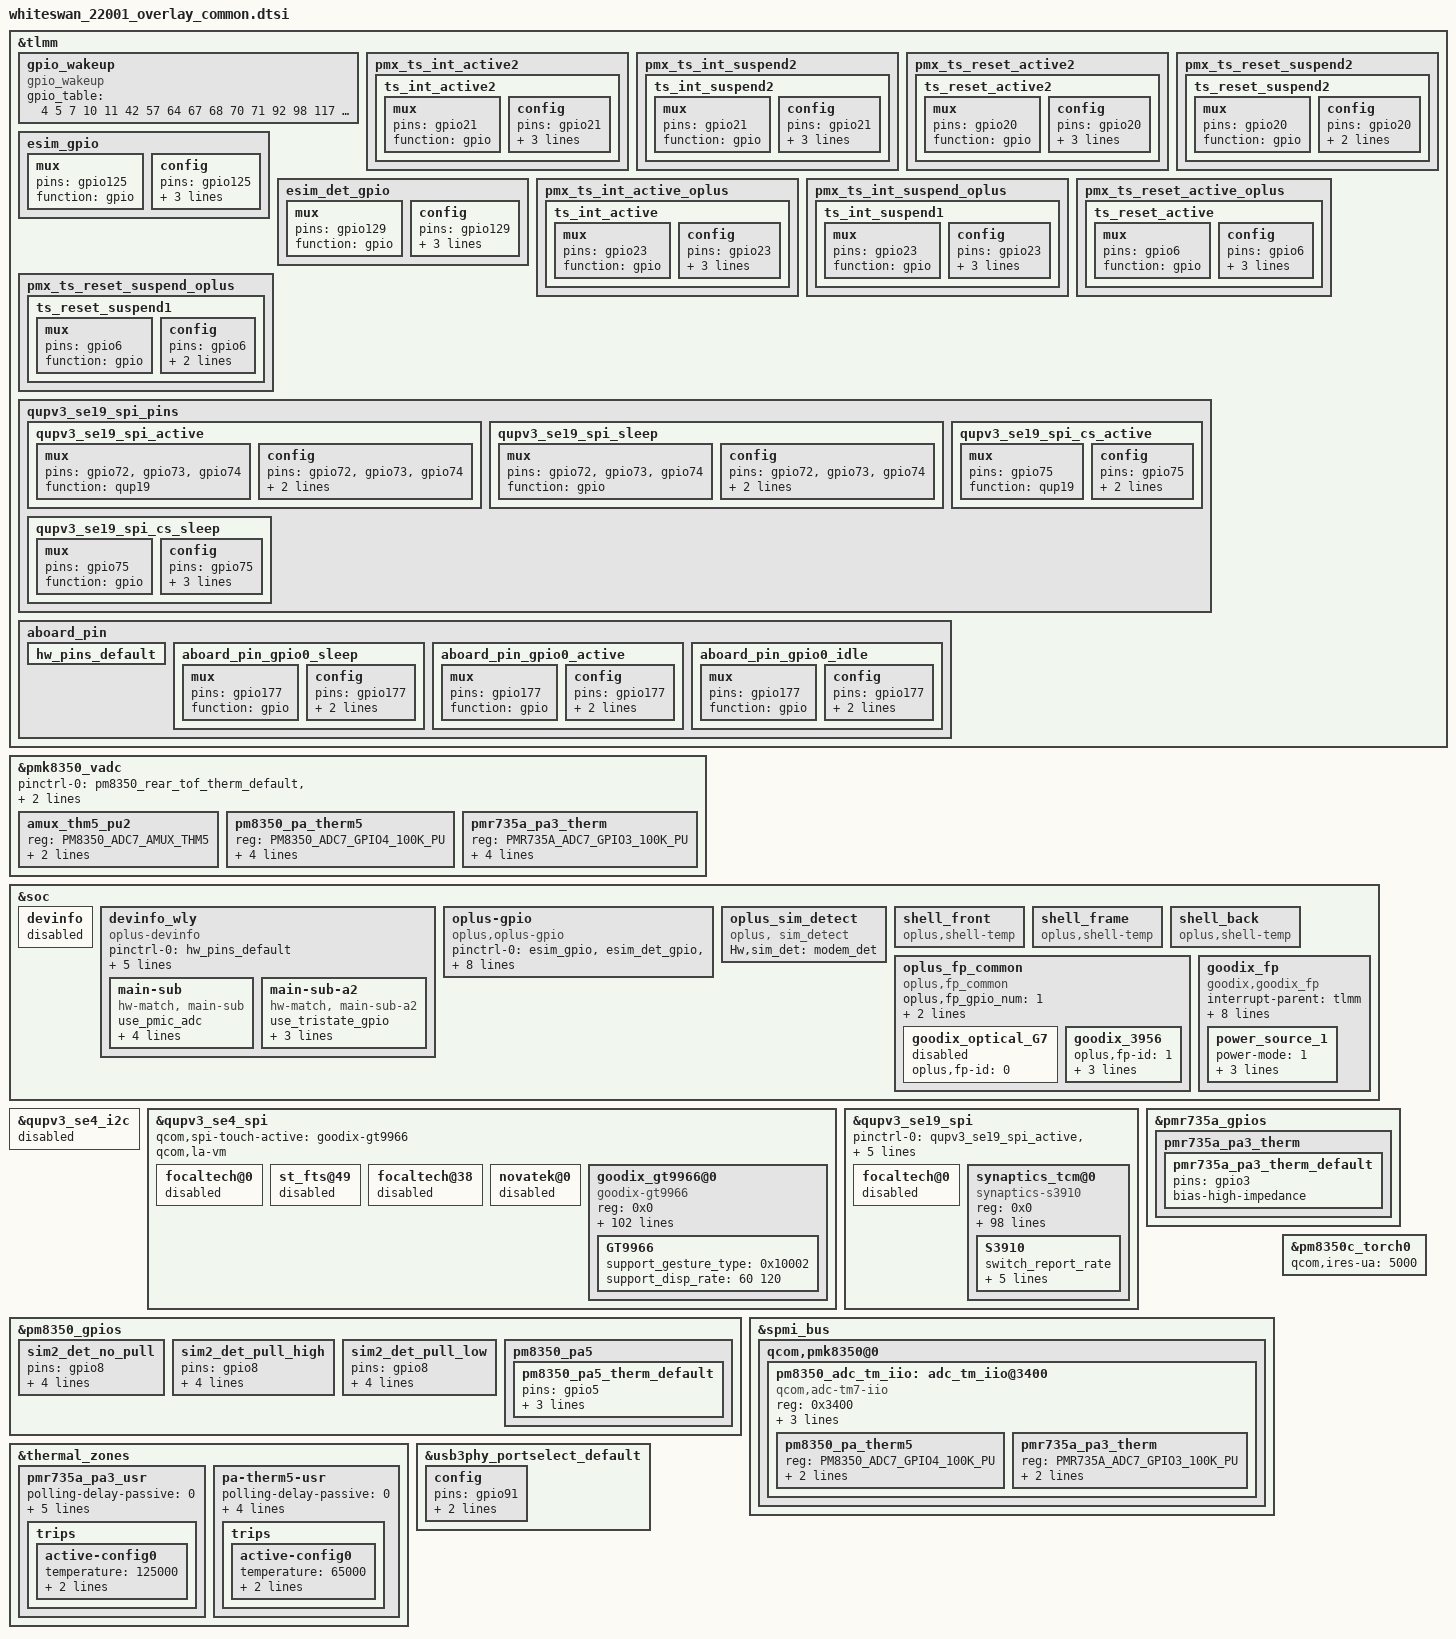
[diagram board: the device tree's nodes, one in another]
&tlmm {
	//#ifdef OPLUS_FEATURE_TP_BASIC
	/* add pingrp for touchscreen */

	gpio_wakeup: gpio_wakeup {
		compatible = "gpio_wakeup";
		gpio_table = <4 5 7 10 11 42 57 64 67 68
				70 71 92 98 117 126 144 145
				151 152 153 155 159 160 161
				171 172 173 178 181 194 195
				205 206 207>;
	};

	pmx_ts_int_active2 {
		ts_int_active2: ts_int_active2 {
			mux {
				pins = "gpio21";
				function = "gpio";
			};

			config {
				pins = "gpio21";
				drive-strength = <8>;
				bias-disable;
				input-enable;
			};
		};
	};

	pmx_ts_int_suspend2 {
		ts_int_suspend2: ts_int_suspend2 {
			mux {
				pins = "gpio21";
				function = "gpio";
			};

			config {
				pins = "gpio21";
				drive-strength = <8>;
				//bias-pull-down;
				bias-pull-up;
				input-enable;
			};
		};
	};

	pmx_ts_reset_active2 {
		ts_reset_active2: ts_reset_active2 {
			mux {
				pins = "gpio20";
				function = "gpio";
			};

			config {
				pins = "gpio20";
				drive-strength = <8>;
				output-low;
				bias-disable;
			};
		};
	};

	pmx_ts_reset_suspend2 {
		ts_reset_suspend2: ts_reset_suspend2 {
			mux {
				pins = "gpio20";
				function = "gpio";
			};

			config {
				pins = "gpio20";
				drive-strength = <2>;
				bias-pull-down;
			};
		};
	};
	//#endif

	//#ifdef OPLUS_FEATRUE_ESIM
	esim_gpio: esim_gpio {
		mux {
			pins = "gpio125";
			function = "gpio";
		};
		config {
			pins = "gpio125";
			bias-disable; /* NO pull */
			drive-strength = <2>; /* 2 MA */
			output-high;
		};
	};

	esim_det_gpio: esim_det_gpio {
		mux {
			pins = "gpio129";
			function = "gpio";
		};
		config {
			pins = "gpio129";
			bias-disable; /* NO pull */
			drive-strength = <2>; /* 2 MA */
			output-high;
		};
	};
	//#endif /* OPLUS_FEATRUE_ESIM */

	//#ifdef OPLUS_FEATURE_TP_BASIC
	/* add pingrp for touchscreen */
	pmx_ts_int_active_oplus {
		ts_int_active: ts_int_active {
			mux {
				pins = "gpio23";
				function = "gpio";
			};

			config {
				pins = "gpio23";
				drive-strength = <8>;
				bias-disable;
				input-enable;
			};
		};
	};

	pmx_ts_int_suspend_oplus {
		ts_int_suspend1: ts_int_suspend1 {
			mux {
				pins = "gpio23";
				function = "gpio";
			};

			config {
				pins = "gpio23";
				drive-strength = <8>;
				bias-pull-up;
				input-enable;
			};
		};
	};

	pmx_ts_reset_active_oplus {
		ts_reset_active: ts_reset_active {
			mux {
				pins = "gpio6";
				function = "gpio";
			};

			config {
				pins = "gpio6";
				drive-strength = <8>;
				output-low;
				bias-disable;
			};
		};
	};

	pmx_ts_reset_suspend_oplus {
		ts_reset_suspend1: ts_reset_suspend1 {
			mux {
				pins = "gpio6";
				function = "gpio";
			};

			config {
				pins = "gpio6";
				drive-strength = <2>;
				bias-pull-down;
			};
		};
	};
	//#endif

	qupv3_se19_spi_pins: qupv3_se19_spi_pins {
		qupv3_se19_spi_active: qupv3_se19_spi_active {
			mux {
				pins = "gpio72", "gpio73",
						"gpio74";
				function = "qup19";
			};

			config {
				pins = "gpio72", "gpio73",
						"gpio74";
				drive-strength = <6>;
				bias-disable;
			};
		};

		qupv3_se19_spi_sleep: qupv3_se19_spi_sleep {
			mux {
				pins = "gpio72", "gpio73",
						"gpio74";
				function = "gpio";
			};

			config {
				pins = "gpio72", "gpio73",
						"gpio74";
				drive-strength = <6>;
				bias-disable;
			};
		};

		qupv3_se19_spi_cs_active: qupv3_se19_spi_cs_active {
			mux {
				pins = "gpio75";
				function = "qup19";
			};

			config {
				pins ="gpio75";
				drive-strength = <6>;
				bias-disable;
			};
		};
		qupv3_se19_spi_cs_sleep: qupv3_se19_spi_cs_sleep {
			mux {
				pins = "gpio75";
				function = "gpio";
			};

			config {
				pins = "gpio75";
				drive-strength = <6>;
				bias-disable;
				output-high;
			};
		};
	};
//#endif /*OPLUS_FEATURE_TP_BASIC*/

	aboard_pin {
		hw_pins_default:hw_pins_default {
		};

		aboard_pin_gpio0_sleep:aboard_pin_gpio0_sleep {
			mux {
				pins = "gpio177";
				function = "gpio";
			};

			config {
				pins = "gpio177";
				bias-pull-down;
				input-enable;
			};
		};

		aboard_pin_gpio0_active:aboard_pin_gpio0_active {
			mux {
				pins = "gpio177";
				function = "gpio";
			};

			config {
				pins = "gpio177";
				bias-pull-up;
				input-enable;
			};
		};

		aboard_pin_gpio0_idle:aboard_pin_gpio0_idle {
			mux {
				pins = "gpio177";
				function = "gpio";
			};

			config {
				pins = "gpio177";
				bias-disable;
				input-enable;
			};
		};
	};
};

&pmk8350_vadc {
	amux_thm5_pu2 {
		reg = <PM8350_ADC7_AMUX_THM5>;
		label = "gpio1b_v";
		qcom,pre-scaling = <1 1>;
	};
};

&soc {
        devinfo {
		status = "disabled";
	};

	devinfo_wly {
		compatible = "oplus-devinfo";

		pinctrl-names = "default", "sleep", "active", "idle";
		pinctrl-0 = <&hw_pins_default>;
		pinctrl-1 = <&aboard_pin_gpio0_sleep>;
		pinctrl-2 = <&aboard_pin_gpio0_active>;
		pinctrl-3 = <&aboard_pin_gpio0_idle>;

		io-channels= <&pmk8350_vadc PM8350_ADC7_AMUX_THM5>;
		io-channel-names= "vph_pwr_voltage_sub";

		main-sub {
			compatible = "hw-match, main-sub";
			use_pmic_adc;
			adc_ranges = <0 80
					81 180
					181 300
					301 420
					421 550
					551 650
					651 760
					761 850
					851 950
					951 1050
					1051 1150
					1151 1300>;
			aboard-patterns = <0 1>;

			/*main board*/
			match-projects = <22001 22201>;
		};

		main-sub-a2 {
			compatible = "hw-match, main-sub-a2";
			use_tristate_gpio;
			aboard-gpio0 = <&tlmm 177 0>;
			aboard-patterns = <0 1>;	/*0[high-resistance] 1[pull-down] 2[pull-up]*/
			/*main board*/
			match-projects = <22001 22201>;
		};
	};

	//#ifdef OPLUS_FEATRUE_ESIM
	oplus-gpio {
		compatible = "oplus,oplus-gpio";
		pinctrl-names = "default", "sim2_det_no_pull", "sim2_det_pull_high", "sim2_det_pull_low";
		pinctrl-0 = <&esim_gpio &esim_det_gpio &sim2_det_no_pull>;
		pinctrl-1 = <&sim2_det_no_pull>;
		pinctrl-2 = <&sim2_det_pull_high>;
		pinctrl-3 = <&sim2_det_pull_low>;
		oplus,oplus-gpio-esim = <&tlmm 125 0>;
		oplus,oplus-esim-det = <&tlmm 129 0>;
		oplus,oplus-sim2-det = <&pm8350_gpios 8 0>;
		oplus,uim-reset-pin = "modem_solution";
	};
	//#endif /* OPLUS_FEATRUE_ESIM */

	//#ifdef OPLUS_FEATRUE_SIM_HOLDER_DETECT
	oplus_sim_detect {
		compatible = "oplus, sim_detect";
		Hw,sim_det = "modem_det";
	};
};

//#ifdef /*OPLUS_FEATURE_TP_BASIC*/
&qupv3_se4_i2c {
	status = "disabled";
};
&qupv3_se4_spi {
	status = "ok";
	#address-cells = <1>;
	#size-cells = <0>;

	qcom,spi-touch-active = "goodix-gt9966";
	qcom,la-vm;

	/delete-node/ focaltech@0;
	focaltech@0 {
		status = "disabled";
	};
	st_fts@49 {
		status = "disabled";
	};
	focaltech@38 {
		status = "disabled";
	};
	novatek@0 {
		status = "disabled";
	};

	goodix_gt9966@0 {
		status = "ok";
		compatible = "goodix-gt9966";
		reg = <0x0>;
		spi-max-frequency = <12000000>;
		chip-name = "GT9966";

		/* Interrupt && Irq-gpio */
		irq-gpio = <&tlmm 21 0x2002>;
		interrupt-parent = <&tlmm>;
		interrupts = <21 0x2002>;
		reset-gpio = <&tlmm 20 0x1>;

		/* Power Config */
		enable2v8_gpio = <&tlmm 56 0x1>;
		vdd_2v8_volt = <3008000>;
		vcc_1v8-supply = <&L4H>;

		/* Other HW Resource */
		pinctrl-names = "default";
		pinctrl-0 = <&ts_int_active2 &ts_reset_active2>;

		touchpanel,max-num-support = <10>;
		touchpanel,tx-rx-num = <32 34>;
		earsense,tx-rx-num = <32 34>;
		touchpanel,panel-coords = <19200 17920>;
		touchpanel,display-coords = <1920 1792>;
		touchpanel,touchmajor-limit = <128 216>;
		touchpanel,single-optimized-time = <8>;
		touchpanel,high-frame-rate-time = <60>;

		touchpanel,pen-tx-rx-num = <32 34>;
		touchpanel,pen-panel-coords = <19200 17920>;
		touchpanel,pen-max-pressure = <4096>;
		touchpanel,pen-max-tilt = <60 60>;
		touchpanel,msecs-to-jiffies-time = <100>;

		touchpanel,smooth-level = <0 121 152 183 229 241>;
		touchpanel,smooth-level-charging = <0 121 152 183 229 241>;
		touchpanel,sensitive-level = <0 100 90 70 60 51>;

		project_id = <22001>;
		vid_len = <2>;
		touchpanel,tp-index = <0>;
		touchpanel,tp_ic_type = <2>;
		panel_type = <3>;
		// type of tp_dev ,TP-BOE = 3;
		firmware_name = "AA381", "AA381";
		platform_support_project = <22001 22201>;
		platform_support_project_dir = <22001 22001>;
		platform_support_project_commandline = "dsi_oplus_samsung_s6e3xa2_1792_1920_dsc_cmd",
							"dsi_oplus_samsung_s6e3xa2_1792_1920_dsc_cmd";

		prevention,curved_screen_V2;
		prevention,grip_disable_level = <6>;
		prevention,updelay_time_ms = <45>;
		prevention,makeup_cnt_weight = <5 1 2 2 2>;
		prevention,large_corner_range = <1200 3000>;
		prevention,large_corner_judge_condition = <850 100 1000 7 7>;
		prevention,trx_reject_condition = <7 7 7>;
		prevention,trx_strict_reject_condition = <8 6 6>;
		prevention,large_judge_time_ms = <500 50 30>;
		prevention,large_exit_condition = <8 8 2>;
		prevention,single_channel_width = <320 320>;
		prevention,normal_tap_condition = <10 350>;
		prevention,long_edge_condition = <240 150 180 80>;
		prevention,long_strict_edge_condition = <160 60>;
		prevention,long_fingerhold_condition = <70 6 4 4>;
		prevention,short_edge_condition = <250 90 180 80>;
		prevention,short_strict_edge_condition = <160 60>;
		prevention,large_strict_exit_condition = <4 4>;
		prevention,top_corner_config = <500 1500 300>;
		prevention,edge_swipe_config = <300 1000>;

		trusted_touch_support;
		/* irq_tui_flags should be the opposite of the irq_flags configuration */
		touchpanel,irq_tui_flags = <0x1>;	/* 0x1:IRQ_TYPE_EDGE_RISING */
		touchpanel,trusted-touch-mode = "vm_mode";
		touchpanel,touch-environment = "pvm";
		touchpanel,trusted-touch-type = "primary";
		touchpanel,trusted-touch-spi-irq = <754>;
		touchpanel,trusted-touch-io-bases = <0x990000 0x910000>;
		touchpanel,trusted-touch-io-sizes = <0x1000 0x4000>;
		touchpanel,trusted-touch-vm-gpio-list = <&tlmm 16 0 &tlmm 17 0 &tlmm 18 0
						&tlmm 19 0 &tlmm 20 0 &tlmm 21 0x2002>;
		touchpanel,trusted-touch-reset-io-base = <0xF114000>;
		touchpanel,trusted-touch-reset-io-size = <0x1000>;
		touchpanel,trusted-touch-reset-io-offset = <0x4>;
		touchpanel,trusted-touch-irq-io-base = <0xF115000>;
		touchpanel,trusted-touch-irq-io-size = <0x1000>;
		touchpanel,trusted-touch-irq-io-offset = <0x8>;

		black_gesture_support;
		pressure_report_support;
		charger_pump_support;
		game_switch_support;
		smart_gesture_support;
		spi_port_support;
		fw_update_app_support;
		//fingerprint_underscreen_support;
		freq_hop_simulate_support;
		report_flow_unlock_support;
		//screenoff_fingerprint_info_support;
		irq_need_dev_resume_ok;
		//enable_point_auto_change;
		//report_rate_white_list_support;
		kernel_grip_support;
		exception_upload_support;
		//grip_no_driver_support;
		health_monitor_support;
		black_gesture_indep_support;
		//algorithm_support;
		//snr_read_support;
		//touchpanel,get_motor_coord = <0 370 70>;
		sportify_aod_gesture_support;
		pen_support;

		temperature_detect_support;
		io-channels = <&pmk8350_vadc PM8350_ADC7_AMUX_THM3_100K_PU>;
		io-channel-names = "pm8350_hot_pocket_therm";
		oplus,skin_temp_chan = "pm8350_hot_pocket_therm";

		/*
		 *Virtual Key Config:
		 *1:touchpanel,button-type: <virtualkey_type  supportted_button-map>
		 *virtualkey_type:
		 *Type 1: using board_properties
		 *Type 2: using same IC (button zone&& touch zone are seprate)
		 *Type 3: using diffrent IC (button zone&& touch zone are seprate)
		 *Type 4: No need of virtual key process
		 *supportted_button-map:select|menu|home|back
		 *
		 *2:touchpanel,button-map
		 *type (X1,Y1)(X2,Y2)(X3,Y3)(Width_X,Hight_Y)--Only when button-type is 0
		 */
		touchpanel,button-type = <4>;
		touchpanel.button-TRx = <0 0>;

		GT9966 {
			support_gesture_type = <0x10002>;
			support_disp_rate = <60 120>;
		};

	};
//#endif /*OPLUS_FEATURE_TP_BASIC*/
};

&qupv3_se19_spi{
	/delete-property/ pinctrl-0;
	/delete-property/ pinctrl-1;
	pinctrl-0 = <&qupv3_se19_spi_active &qupv3_se19_spi_cs_active>;
	pinctrl-1 = <&qupv3_se19_spi_sleep &qupv3_se19_spi_cs_sleep>;
};

&qupv3_se19_spi {
	status = "ok";

	#address-cells = <1>;
	#size-cells = <0>;
	qcom,spi-touch-active = "synaptics-s3910";
	qcom,la-vm;

	focaltech@0 {
		status = "disabled";
	};
	synaptics_tcm@0{
		compatible = "synaptics-s3910";
		reg = <0x0>;
		chip-name = "S3910";
		spi-max-frequency = <12000000>;
		/* Interrupt && Irq-gpio */
		/* Interrupt && Irq-gpio */
		interrupt-parent = <&tlmm>;
		interrupts = <23 0x2008>;

		/* Power Config */
		vdd_2v8-supply = <&L9C>;
		vcc_1v8-supply = <&L4H>;
		vdd_2v8_volt = <2960000>;

		/* Other HW Resource */
		irq-gpio = <&tlmm 23 0x2008>;
		reset-gpio = <&tlmm 6 0x1>;
		pinctrl-names = "default";
		pinctrl-0 = <&ts_int_active &ts_reset_active>;

		touchpanel,max-num-support = <10>;
		touchpanel,tx-rx-num = <16 32>;
		touchpanel,panel-coords = <10800 21200>;
		touchpanel,display-coords = <1080 2120>;
		touchpanel,touchmajor-limit = <128 216>;
		touchpanel,elimination-range = <20 200 200>;
		touchpanel,int-mode = <1>; /*0: interrupt and disable, 1:interrupt and not disable*/
		touchpanel,smooth-level = <0 1 2 4 7 9>;
		touchpanel,smooth-level-charging = <0 2 4 7 8 9>;
		touchpanel,sensitive-level = <0 70 55 40 25 10>;
		touchpanel,single-optimized-time = <8>;
		touchpanel,high-frame-rate-time = <60>;

		project_id = <22001>;
		vid_len = <2>;
		touchpanel,tp-index = <1>;
		touchpanel,tp_ic_type = <2>;
		panel_type = <3>;
		// type of tp_dev ,TP-SAMSUNG = 8;
		platform_support_project = <22001 22201>;
		platform_support_project_dir = <22001 22001>;
		platform_support_project_commandline = "dsi_oplus_samsung_s6e3fac_1080_2120_dsc_cmd",
							"dsi_oplus_samsung_s6e3fac_1080_2120_dsc_cmd";

		prevention,curved_screen_V2;
		prevention,grip_disable_level = <6>;
		prevention,updelay_time_ms = <45>;
		prevention,makeup_cnt_weight = <5 1 2 2 2>;
		prevention,large_corner_range = <1200 3000>;
		prevention,large_corner_judge_condition = <850 100 1000 7 7>;
		prevention,trx_reject_condition = <8 7 7>;
		prevention,trx_strict_reject_condition = <8 6 6>;
		prevention,large_judge_time_ms = <500 50 30>;
		prevention,large_exit_condition = <8 8 2>;
		prevention,single_channel_width = <320 320>;
		prevention,normal_tap_condition = <10 350>;
		prevention,long_edge_condition = <240 150 180 80>;
		prevention,long_strict_edge_condition = <160 60>;
		prevention,long_fingerhold_condition = <70 6 4 4>;
		prevention,short_edge_condition = <250 90 180 80>;
		prevention,short_strict_edge_condition = <160 60>;
		prevention,large_strict_exit_condition = <6 6>;
		prevention,top_corner_config = <500 1500 300>;
		prevention,edge_swipe_config = <300 1000>;

		trusted_touch_support;
		touchpanel,irq_tui_flags = <0x4>;	/* 0x4:IRQ_TYPE_LEVEL_HIGH */
		touchpanel,trusted-touch-mode = "vm_mode";
		touchpanel,touch-environment = "pvm";
		touchpanel,trusted-touch-type = "secondary";
		touchpanel,trusted-touch-spi-irq = <566>;
		touchpanel,trusted-touch-io-bases = <0x890000 0x810000>;
		touchpanel,trusted-touch-io-sizes = <0x1000 0x4000>;
		touchpanel,trusted-touch-vm-gpio-list = <&tlmm 72 0 &tlmm 73 0 &tlmm 74 0
					&tlmm 75 0 &tlmm 6 0 &tlmm 23 0x2008>;
		touchpanel,trusted-touch-reset-io-base = <0xF106000>;
		touchpanel,trusted-touch-reset-io-size = <0x1000>;
		touchpanel,trusted-touch-reset-io-offset = <0x4>;
		touchpanel,trusted-touch-irq-io-base = <0xF117000>;
		touchpanel,trusted-touch-irq-io-size = <0x1000>;
		touchpanel,trusted-touch-irq-io-offset = <0x8>;

		/* SW Support Feature Control */
		black_gesture_support;
		pressure_report_support;
		charger_pump_support;
		game_switch_support;
		smart_gesture_support;
		spi_port_support;
		fw_update_app_support;
	        fingerprint_underscreen_support;
		freq_hop_simulate_support;
		report_flow_unlock_support;
		screenoff_fingerprint_info_support;
		irq_need_dev_resume_ok;
		enable_point_auto_change;
		report_rate_white_list_support;
		kernel_grip_support;
		exception_upload_support;
		//grip_no_driver_support;
		health_monitor_support;
		black_gesture_indep_support;
		algorithm_support;
		snr_read_support;
		sportify_aod_gesture_support;
		palm_to_sleep_support;
		/*
		 *Virtual Key Config:
		 *1:touchpanel,button-type: <virtualkey_type  supportted_button-map>
		 *virtualkey_type:
		 *Type 1: using board_properties
		 *Type 2: using same IC (button zone&& touch zone are seprate)
		 *Type 3: using diffrent IC (button zone&& touch zone are seprate)
		 *Type 4: No need of virtual key process
		 *supportted_button-map:select|menu|home|back
		 *
		 *2:touchpanel,button-map
		 *type (X1,Y1)(X2,Y2)(X3,Y3)(Width_X,Hight_Y)--Only when button-type is 0
		 */
		touchpanel,button-type = <4>;
		touchpanel.button-TRx = <0 0>;

		S3910 {
			switch_report_rate;
			report_rate_default = <60>;
			report_rate_game_value = <0x03>;
			fps_report_rate = <60 2 90 3 120 3>;//1:360Hz 2:125Hz 3:240Hz
			fwupdate_bootloader = <1>;
			default_gesture_mask = <8191>;
		};
	};

};
//#endif /*OPLUS_FEATURE_TP_BASIC*/

&pm8350_gpios {
	//#ifdef OPLUS_FEATRUE_DUAL_SIM_DETECT
	sim2_det_no_pull: sim2_det_no_pull {
			pins = "gpio8";
			function = "normal";
			input-enable;
			power-source = <1>;
			bias-disable;
	};

	sim2_det_pull_high: sim2_det_pull_high {
			pins = "gpio8";
			function = "normal";
			input-enable;
			power-source = <1>;
			bias-pull-up;
	};

	sim2_det_pull_low: sim2_det_pull_low {
			pins = "gpio8";
			function = "normal";
			input-enable;
			power-source = <1>;
			bias-pull-down;
	};
	//#endif OPLUS_FEATRUE_DUAL_SIM_DETECT
};

//#ifdef OPLUS_FEATURE_THERMAL
&pmr735a_gpios {
	pmr735a_pa3_therm {
         pmr735a_pa3_therm_default: pmr735a_pa3_therm_default {
               pins = "gpio3";
               bias-high-impedance;
         };
      };
};

&pm8350_gpios {
	pm8350_pa5 {
		pm8350_pa5_therm_default: pm8350_pa5_therm_default {
			pins = "gpio5";
			function = "normal";
			bias-high-impedance;
			bias-disable;
		};
	};
};

&pmk8350_vadc {
	pinctrl-names = "default";
	pinctrl-0 = <&pm8350_rear_tof_therm_default &pm8350_pa5_therm_default &pmr735a_pa3_therm_default>;
	pm8350_pa_therm5 {
		reg = <PM8350_ADC7_GPIO4_100K_PU>;
		label = "pm8350_pa_therm5";
		qcom,ratiometric;
		qcom,hw-settle-time = <200>;
		qcom,pre-scaling = <1 1>;
	};

	pmr735a_pa3_therm {
		reg = <PMR735A_ADC7_GPIO3_100K_PU>;
		label = "pmr735a_pa3_therm";
		qcom,ratiometric;
		qcom,hw-settle-time = <200>;
		qcom,pre-scaling = <1 1>;
	};
};

&spmi_bus {
	qcom,pmk8350@0 {
		pm8350_adc_tm_iio: adc_tm_iio@3400 {
			/* Alternate ADC_TM DT node */
			compatible = "qcom,adc-tm7-iio";
			/* With this entry, a feature-reduced
			version of the driver is initialized (only
			thermistor reads, no interrupt functionality
			for exposed thermistors) */
			reg = <0x3400>;
			#thermal-sensor-cells = <1>;
			#address-cells = <1>;
			#size-cells = <0>;
			io-channels = <&pmk8350_vadc PMR735A_ADC7_GPIO3_100K_PU>,
						<&pmk8350_vadc PM8350_ADC7_GPIO4_100K_PU>;
			/* Similar to io-channels in actual ADC_TM node,
			for reading thermistor temperature from
			VADC */

			pm8350_pa_therm5 {
				/* ADC_TM child node, similar to previous */
				reg = <PM8350_ADC7_GPIO4_100K_PU>;
				qcom,ratiometric;
				qcom,hw-settle-time = <200>;
			};

			pmr735a_pa3_therm {
				reg = <PMR735A_ADC7_GPIO3_100K_PU>;
				qcom,ratiometric;
				qcom,hw-settle-time = <200>;
			};

		};
	};
};

&thermal_zones {
	pmr735a_pa3_usr {
		polling-delay-passive = <0>;
		polling-delay = <0>;
		thermal-governor = "user_space";
		thermal-sensors = <&pm8350_adc_tm_iio PMR735A_ADC7_GPIO3_100K_PU>;
		wake-capable-sensor;
		trips {
			active-config0 {
				temperature = <125000>;
				hysteresis = <1000>;
				type = "passive";
			};
		};
	};

	pa-therm5-usr {
		polling-delay-passive = <0>;
		polling-delay = <0>;
		thermal-sensors = <&pm8350_adc_tm_iio PM8350_ADC7_GPIO4_100K_PU>;
		/* phandle and channel number of added channel */
		wake-capable-sensor;
		trips {
			active-config0 {
				temperature = <65000>;
				hysteresis = <1000>;
				type = "passive";
			};
		};
	};
};
//#endif OPLUS_FEATURE_THERMAL

//#ifdef OPLUS_FEATURE_THERMAL_HORAE
&soc {
	shell_front {
			compatible = "oplus,shell-temp";
	};

	shell_frame {
			compatible = "oplus,shell-temp";
	};

	shell_back {
			compatible = "oplus,shell-temp";
	};
};
//#endif OPLUS_FEATURE_THERMAL_HORAE

&soc {
	//#ifdef OPLUS_FEATURE_FINGERPRINT
	oplus_fp_common {
		compatible = "oplus,fp_common";
		oplus,fp_gpio_num = <1>;
		oplus,fp_gpio_0 = <&tlmm 42 0x0>;
		pinctrl-names = "default";
		pinctrl-0 = <&gpio_id2_default>;
		/delete-node/ goodix_optical_G7;
		goodix_optical_G7 {
			status = "disabled";
			oplus,fp-id = <0>;
		};
		goodix_3956 {
			oplus,fp-id = <1>; /* fp id mapping table */
			vendor-chip = <19>; /* please refer to the struct fp_vendor_t in oplus_fp_commmon.n */
			eng-menu = "-1,-1"; /* represents SNR, inclination test item in engineer menu, and 0/1 means off/on */
			chip-name = "GF3956";  /* /proc/fp_id, will be displayed in engineer menu  */
		};
	};
	goodix_fp {
		status = "ok";
		compatible = "goodix,goodix_fp";
		interrupt-parent = <&tlmm>;
		interrupts = <40 0>;
		ldo-supply = <&pm8350c_l11>;
		ldo-config = <3000000 3000000 150000>;
		goodix,gpio_irq = <&tlmm 40 0x1>;
		goodix,gpio_reset = <&tlmm 41 0x0>;
		pinctrl-names = "default";
		pinctrl-0 = <&gpio_goodix_irq_default>;
		notify_tpinfo_flag = <0>;
		power-num = <1>;
		power_source_1 {
			power-mode = <1>;
			power-name = "ldo";
			power-config = "ldo-config";
			delay-time = <0>;
		};
	};
	//#endif /*OPLUS_FEATURE_FINGERPRINT*/
};

&usb3phy_portselect_default {
	config {
		pins = "gpio91";
		bias-pull-down;
		drive-strength = <2>;
	};
};
&pm8350c_torch0 {
	qcom,ires-ua = <5000>;
};
